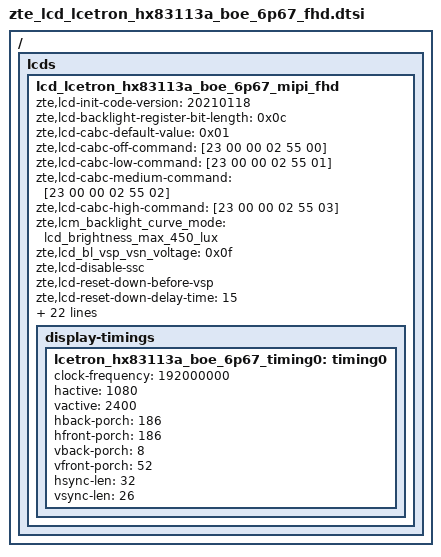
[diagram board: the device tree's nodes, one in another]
/ { lcds {
	lcd_lcetron_hx83113a_boe_6p67_mipi_fhd: lcd_lcetron_hx83113a_boe_6p67_mipi_fhd {
		zte,lcd-init-code-version = "20210118";
		zte,lcd-backlight-register-bit-length = <0x0c>;
		zte,lcd-cabc-default-value = <0x01>;
		zte,lcd-cabc-off-command = [23 00 00 02 55 00];
		zte,lcd-cabc-low-command = [23 00 00 02 55 01];
		zte,lcd-cabc-medium-command = [23 00 00 02 55 02];
		zte,lcd-cabc-high-command = [23 00 00 02 55 03];
		zte,lcm_backlight_curve_mode = "lcd_brightness_max_450_lux";
		zte,lcd_bl_vsp_vsn_voltage = <0x0f>;
		zte,lcd-disable-ssc;
		zte,lcd-reset-down-before-vsp;
		zte,lcd-reset-down-delay-time = <15>;
		zte,panel-name = "lcd_lianchuang_hx83113a_boe_6p67_mipi_fhd";

		sprd,dsi-work-mode = <1>; /* video burst mode*/
		sprd,dsi-lane-number = <4>;
		sprd,dsi-color-format = "rgb888";

		sprd,phy-bit-clock = <1280000>;  /* kbps */
		sprd,phy-escape-clock = <20000>;/* kHz */

		sprd,width-mm = <69498>;
		sprd,height-mm = <154440>;

		sprd,esd-check-enable = <1>;/* 0:close , 1:open */
		sprd,esd-check-mode = <0>;/* 0:REG ,1:TE  */
		sprd,esd-check-period = <3000>;
		sprd,esd-check-register = <0x0A>;
		sprd,esd-check-value = <0x9D>;

		sprd,reset-on-sequence = <1 10>, <0 5>, <1 55>;
		sprd,reset-off-sequence = <1 5>;

		sprd,initial-command = [
			39 00 00 04 b9 83 11 3a
			39 00 00 02 CD 01
			39 00 00 0C b1 4c 27 27 85 80 a8 a8 28 28
						01 01
			39 00 00 16 b2 00 33 80 90 60 00 20 32 00
						04 00 CE 11 01 00 00 00 00 80
						10 a3
			39 00 00 1E b4 02 de 02 de 02 de 04 da 02
						da 02 da 04 da 00 00 09 0c 00
						19 00 05 05 07 00 00 00 00 85
			39 05 00 2F e0 00 14 30 3a 49 78 7e 82 82
						7d 7d 7f 80 82 82 82 86 84 86
						9d b9 50 76 00 14 30 3a 49 78
						7e 82 82 7d 7d 7f 80 82 82 82
						86 84 86 9d b9 50 76
			39 05 00 24 d3 c1 14 01 01 00 12 01 01 03
						01 03 03 0b 0b 05 05 10 04 32
						10 0a 00 0a 32 10 00 00 00 32
						10 0a 00 0a 00 00
			39 05 00 31 d5 41 41 41 41 18 18 40 40 18
						18 18 18 34 34 31 31 33 33 30
						30 32 32 2f 2f 18 18 18 18 18
						18 18 18 01 00 03 02 be be 41
						41 41 41 19 19 40 40 21 20
			39 05 00 31 d6 41 41 41 41 18 18 40 40 18
						18 18 18 34 34 31 31 33 33 30
						30 32 32 2f 2f 18 18 18 18 18
						18 18 18 02 03 00 01 be be 41
						41 41 41 40 40 19 19 20 21
			39 00 00 19 d8 aa aa aa aa ff ea aa aa aa
						aa ff ea aa aa aa aa ff ea aa
						aa aa aa ff ea
			39 00 00 07 c0 23 23 44 ff 12 5a
			39 00 00 05 cb 5f 19 12 2D
			39 00 00 02 cc 0a
			39 00 00 3E df 07 00 00 00 ff ff ff a5 42
						67 ee 54 2a 74 e6 4e a5 42 67
						ee 54 2a 74 e6 4e a5 42 67 ee
						54 2a 74 e6 4e a5 42 67 ee 54
						2a 74 e6 4e a1 3a 87 ea 1c aa
						73 a8 ce a1 3a 87 ea 1c aa 73
						a8 ce
			39 00 00 1E e7 48 3C 09 09 20 84 21 84 00
						84 0a 0a 00 00 02 02 12 05 ff
						ff 21 84 00 84 09 00 00 08 17
			39 00 00 02 e9 c4
			39 00 00 03 d1 0c df
			39 00 00 02 e9 3f
			39 00 00 02 e9 c6
			39 00 00 02 ba 11
			39 00 00 02 e9 3f
			39 00 00 02 e9 c4
			39 00 00 02 bf 04
			39 00 00 02 e9 3f
			39 00 00 02 e9 cb
			39 0A 00 02 e4 00
			39 00 00 02 e9 3f
			39 00 00 02 bd 01
			39 00 00 07 b4 01 19 1b 19 1b 1b
			39 00 00 0D d8 ab ff ff aa ff ff ab ff ff
						aa ff ff
			39 00 00 0D d2 00 00 00 00 00 00 00 00 00
						00 02 17
			39 00 00 04 b1 1b 11 61
			39 00 00 09 e7 02 60 12 01 2a 08 32 09
			39 00 00 04 b1 db 11 01
			39 00 00 02 bd 02
			39 00 00 0D d8 ab ff ff aa ff ff ab ff ff
						aa ff ff
			39 00 00 03 b1 2d 2d
			39 00 00 08 b4 89 22 80 01 22 22 11
			39 00 00 12 e7 02 02 02 00 da 01 03 01 03
						01 03 02 20 08 40 0b 0a
			39 00 00 02 bd 03
			39 00 00 19 d8 ab af ff aa aa be ab af ff
						aa aa be ab ff ff aa ff ff ab
						ff ff aa ff ff
			39 00 00 02 bd 00
			39 00 00 02 b9 00
			39 00 00 02 35 00
			39 00 00 03 51 0F FF
			39 00 00 02 53 2C
			39 00 00 02 55 00
			05 78 00 01 11
			05 14 00 01 29
			];

		sprd,sleep-in-command = [
			13 14 00 01 28
			13 64 00 01 10
			39 00 00 04 B9 83 11 3A
			39 00 00 02 B1 4D
			];
		sprd,sleep-out-command = [
			13 78 00 01 11
			13 14 00 01 29
			];

		display-timings {
			lcetron_hx83113a_boe_6p67_timing0: timing0 {
				clock-frequency = <192000000>;
				hactive = <1080>;
				vactive = <2400>;
				hback-porch = <186>;
				hfront-porch = <186>;
				vback-porch = <8>;
				vfront-porch = <52>;
				hsync-len = <32>;
				vsync-len = <26>;
			};
		};

		/*oled-backlight {
			default-brightness-level = <1638>;
			sprd,max-level = <4095>;
			brightness-levels = [
				39 00 00 03 51 00 00
				39 00 00 02 53 2C
			];
		};*/
	};
}; };
